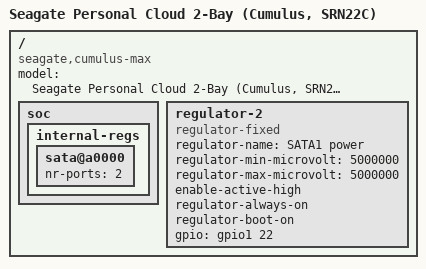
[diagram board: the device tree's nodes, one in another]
/dts-v1/;
#include "armada-370-seagate-personal-cloud.dtsi"
/ {
	model = "Seagate Personal Cloud 2-Bay (Cumulus, SRN22C)";
	compatible = "seagate,cumulus-max", "marvell,armada370", "marvell,armada-370-xp";
	soc {
		internal-regs {
			sata@a0000 {
				status = "okay";
				nr-ports = <2>;
			};
		};
	};
	regulator-2 {
		compatible = "regulator-fixed";
		regulator-name = "SATA1 power";
		regulator-min-microvolt = <5000000>;
		regulator-max-microvolt = <5000000>;
		enable-active-high;
		regulator-always-on;
		regulator-boot-on;
		gpio = <&gpio1 22 GPIO_ACTIVE_HIGH>;
	};
};
